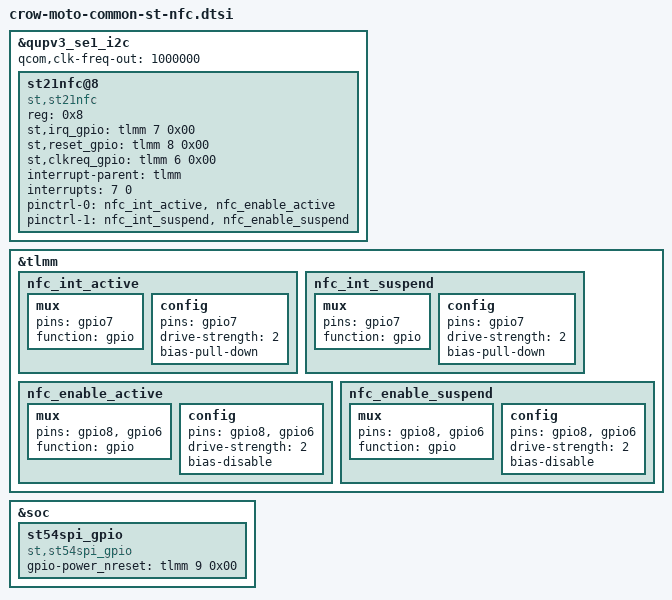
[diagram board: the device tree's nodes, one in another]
/* Copyright (c) 2021, The Linux Foundation. All rights reserved.
 *
 * This program is free software; you can redistribute it and/or modify
 * it under the terms of the GNU General Public License version 2 and
 * only version 2 as published by the Free Software Foundation.
 *
 * This program is distributed in the hope that it will be useful,
 * but WITHOUT ANY WARRANTY; without even the implied warranty of
 * MERCHANTABILITY or FITNESS FOR A PARTICULAR PURPOSE.  See the
 * GNU General Public License for more details.
 */

/* This file is used for 8550 device which use st nfc chipst */

&qupv3_se1_i2c {
        status = "ok";
        qcom,clk-freq-out = <1000000>;
        #address-cells = <1>;
        #size-cells = <0>;
        st21nfc@8 {
                compatible = "st,st21nfc";
                reg = <0x8>;
                st,irq_gpio = <&tlmm 7 0x00>;
                st,reset_gpio = <&tlmm 8 0x00>;
                st,clkreq_gpio = <&tlmm 6 0x00>;
                interrupt-parent = <&tlmm>;
                interrupts = <7 0>;
                interrupt-names = "nfc_irq";
                pinctrl-names = "nfc_active", "nfc_suspend";
                pinctrl-0 = <&nfc_int_active &nfc_enable_active>;
                pinctrl-1 = <&nfc_int_suspend &nfc_enable_suspend>;
        };
};


&tlmm {
        nfc_int_active: nfc_int_active {
                /* active state */
                mux {
                     /* NFC Read Interrupt */
                     pins = "gpio7";
                     function = "gpio";
                };

                config {
                     pins = "gpio7";
                     drive-strength = <2>; /* 2 MA */
                     bias-pull-down;
                };
        };

        nfc_int_suspend: nfc_int_suspend {
                /* sleep state */
                mux {
                     /* NFC Read Interrupt */
                     pins = "gpio7";
                     function = "gpio";
                };

                config {
                     pins = "gpio7";
                     drive-strength = <2>; /* 2 MA */
                     bias-pull-down;
                };
        };

        nfc_enable_active: nfc_enable_active {
                mux {
                     /* Enable, Firmware and Clock request gpios */
                     pins = "gpio8", "gpio6";
                     function = "gpio";
                };

                config {
                     pins = "gpio8", "gpio6";
                     drive-strength = <2>; /* 2 MA */
                     bias-disable;
                };
        };

        nfc_enable_suspend: nfc_enable_suspend {
                mux {
                     pins = "gpio8", "gpio6";
                     function = "gpio";
                };

                config {
                     pins = "gpio8", "gpio6";
                     drive-strength = <2>; /* 2 MA */
                     bias-disable;
                };
        };
};

&soc {
	st54spi_gpio {
		status = "ok";
		compatible = "st,st54spi_gpio";
		/* gpio used as SE_nRESET */
		gpio-power_nreset = <&tlmm 9 0x00>;
	};
};


